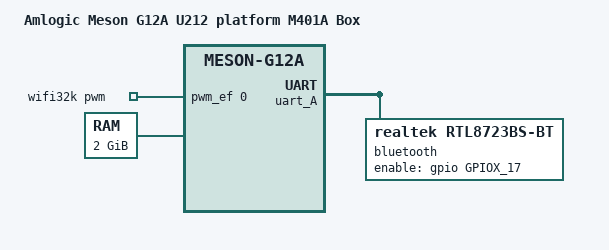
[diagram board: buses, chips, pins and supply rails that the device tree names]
// SPDX-License-Identifier: (GPL-2.0+ OR MIT)
/*
 * Copyright (c) 2018 Amlogic, Inc. All rights reserved.
 * Create by XCray
 */

/dts-v1/;

#include "meson-g12a-u200.dts"

/ {
	compatible = "amlogic,u212\0amlogic,g12a";
	model = "Amlogic Meson G12A U212 platform M401A Box";
	wifi32k: wifi32k {
		compatible = "pwm-clock";
		#clock-cells = <0>;
		clock-frequency = <32768>;
		pwms = <&pwm_ef 0 30518 0>; /* PWM_E at 32.768KHz */
	};
	memory@0 {
		device_type = "memory";
		reg = <0x0 0x0 0x0 0x80000000>;
	};
};
&uart_A {
    status = "okay";
    pinctrl-0 = <&uart_a_pins>, <&uart_a_cts_rts_pins>;
    uart-has-rtscts;
    pinctrl-names = "default";

    bluetooth {
		  compatible = "realtek,rtl8723bs-bt";
		  enable-gpios = <&gpio GPIOX_17 GPIO_ACTIVE_HIGH>;
		  max-speed = <2000000>;
		  clocks = <&wifi32k>;
		  clock-names = "lpo";
	  };
};
